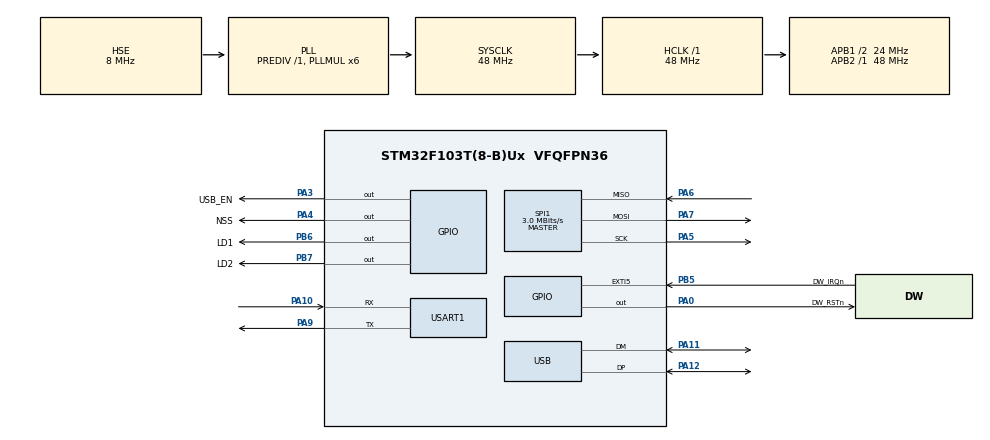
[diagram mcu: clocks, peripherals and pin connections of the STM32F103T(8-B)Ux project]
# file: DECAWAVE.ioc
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Mcu.Family=STM32F1
Mcu.Name=STM32F103T(8-B)Ux
Mcu.Package=VFQFPN36
NVIC.EXTI9_5_IRQn=true\:0\:0\:false\:false\:true\:true\:true\:true
NVIC.PriorityGroup=NVIC_PRIORITYGROUP_4
NVIC.USB_LP_CAN1_RX0_IRQn=true\:0\:0\:false\:false\:true\:false\:true\:true
PA0-WKUP.GPIO_Label=DW_RSTn
PA0-WKUP.GPIO_ModeDefaultOutputPP=GPIO_MODE_OUTPUT_OD
PA0-WKUP.GPIO_PuPd=GPIO_NOPULL
PA0-WKUP.Signal=GPIO_Output
PA10.Mode=Asynchronous
PA10.Signal=USART1_RX
PA11.Mode=Device
PA11.Signal=USB_DM
PA12.Mode=Device
PA12.Signal=USB_DP
PA13.Mode=Serial_Wire
PA13.Signal=SYS_JTMS-SWDIO
PA14.Mode=Serial_Wire
PA14.Signal=SYS_JTCK-SWCLK
PA3.GPIO_Label=USB_EN
PA3.PinState=GPIO_PIN_SET
PA3.Signal=GPIO_Output
PA4.GPIO_Label=NSS
PA4.PinState=GPIO_PIN_SET
PA4.Signal=GPIO_Output
PA5.Mode=Full_Duplex_Master
PA5.Signal=SPI1_SCK
PA6.Mode=Full_Duplex_Master
PA6.Signal=SPI1_MISO
PA7.Mode=Full_Duplex_Master
PA7.Signal=SPI1_MOSI
PA9.Mode=Asynchronous
PA9.Signal=USART1_TX
PB5.GPIO_Label=DW_IRQn
PB5.GPIO_ModeDefaultEXTI=GPIO_MODE_IT_RISING_FALLING
PB5.Signal=GPXTI5
PB6.GPIO_Label=LD1
PB6.PinState=GPIO_PIN_SET
PB6.Signal=GPIO_Output
PB7.GPIO_Label=LD2
PB7.PinState=GPIO_PIN_RESET
PB7.Signal=GPIO_Output
PD0-OSC_IN.Mode=HSE-External-Oscillator
PD0-OSC_IN.Signal=RCC_OSC_IN
PD1-OSC_OUT.Mode=HSE-External-Oscillator
PD1-OSC_OUT.Signal=RCC_OSC_OUT
ProjectManager.HeapSize=0x200
ProjectManager.StackSize=0x400
ProjectManager.TargetToolchain=STM32CubeIDE
RCC.AHBFreq_Value=48000000
RCC.APB1CLKDivider=RCC_HCLK_DIV2
RCC.APB1Freq_Value=24000000
RCC.APB1TimFreq_Value=48000000
RCC.APB2Freq_Value=48000000
RCC.APB2TimFreq_Value=48000000
RCC.HCLKFreq_Value=48000000
RCC.PLLMUL=RCC_PLL_MUL6
RCC.PLLSourceVirtual=RCC_PLLSOURCE_HSE
RCC.SYSCLKFreq_VALUE=48000000
RCC.SYSCLKSource=RCC_SYSCLKSOURCE_PLLCLK
RCC.USBFreq_Value=48000000
SPI1.BaudRatePrescaler=SPI_BAUDRATEPRESCALER_16
SPI1.CLKPolarity=SPI_POLARITY_LOW
SPI1.CalculateBaudRate=3.0 MBits/s
SPI1.Direction=SPI_DIRECTION_2LINES
SPI1.Mode=SPI_MODE_MASTER
SPI1.VirtualType=VM_MASTER
USART1.VirtualMode=VM_ASYNC
USB_DEVICE.CLASS_NAME_FS=CDC
USB_DEVICE.MANUFACTURER_STRING=Agora
USB_DEVICE.VirtualMode=Cdc
USB_DEVICE.VirtualModeFS=Cdc_FS
VP_USB_DEVICE_VS_USB_DEVICE_CDC_FS.Mode=CDC_FS
board=custom

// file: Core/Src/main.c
/* USER CODE BEGIN Header */
/**
 ******************************************************************************
 * @file           : main.c
 * @brief          : Main program body
 ******************************************************************************
 * @attention
 *
 * Copyright (c) 2025 STMicroelectronics.
 * All rights reserved.
 *
 * This software is licensed under terms that can be found in the LICENSE file
 * in the root directory of this software component.
 * If no LICENSE file comes with this software, it is provided AS-IS.
 *
 ******************************************************************************
 */
/* USER CODE END Header */
#include "main.h"
#include "usb_device.h"

/* USER CODE BEGIN Includes */
#include "user_functions.h"

/* USER CODE END Includes */

SPI_HandleTypeDef hspi1;

UART_HandleTypeDef huart1;

void SystemClock_Config(void);
static void MX_GPIO_Init(void);
static void MX_SPI1_Init(void);
static void MX_USART1_UART_Init(void);

int main(void) {

	/* MCU Configuration--------------------------------------------------------*/

	/* Reset of all peripherals, Initializes the Flash interface and the Systick. */
	HAL_Init();

	/* Configure the system clock */
	SystemClock_Config();

	/* Initialize all configured peripherals */
	MX_GPIO_Init();
	MX_SPI1_Init();
	MX_USB_DEVICE_Init();
	MX_USART1_UART_Init();
	/* USER CODE BEGIN 2 */
	setup();
	/* USER CODE END 2 */

	/* Infinite loop */
	while (1) {

		/* USER CODE BEGIN 3 */
		loop();
		/* USER CODE END 3 */
	}
}

void SystemClock_Config(void) {
	RCC_OscInitTypeDef RCC_OscInitStruct = { 0 };
	RCC_ClkInitTypeDef RCC_ClkInitStruct = { 0 };
	RCC_PeriphCLKInitTypeDef PeriphClkInit = { 0 };

	/** Initializes the RCC Oscillators according to the specified parameters
	 * in the RCC_OscInitTypeDef structure.
	 */
	RCC_OscInitStruct.OscillatorType = RCC_OSCILLATORTYPE_HSE;
	RCC_OscInitStruct.HSEState = RCC_HSE_ON;
	RCC_OscInitStruct.HSEPredivValue = RCC_HSE_PREDIV_DIV1;
	RCC_OscInitStruct.HSIState = RCC_HSI_ON;
	RCC_OscInitStruct.PLL.PLLState = RCC_PLL_ON;
	RCC_OscInitStruct.PLL.PLLSource = RCC_PLLSOURCE_HSE;
	RCC_OscInitStruct.PLL.PLLMUL = RCC_PLL_MUL6;
	if (HAL_RCC_OscConfig(&RCC_OscInitStruct) != HAL_OK) {
		Error_Handler();
	}

	/** Initializes the CPU, AHB and APB buses clocks
	 */
	RCC_ClkInitStruct.ClockType = RCC_CLOCKTYPE_HCLK | RCC_CLOCKTYPE_SYSCLK
			| RCC_CLOCKTYPE_PCLK1 | RCC_CLOCKTYPE_PCLK2;
	RCC_ClkInitStruct.SYSCLKSource = RCC_SYSCLKSOURCE_PLLCLK;
	RCC_ClkInitStruct.AHBCLKDivider = RCC_SYSCLK_DIV1;
	RCC_ClkInitStruct.APB1CLKDivider = RCC_HCLK_DIV2;
	RCC_ClkInitStruct.APB2CLKDivider = RCC_HCLK_DIV1;

	if (HAL_RCC_ClockConfig(&RCC_ClkInitStruct, FLASH_LATENCY_1) != HAL_OK) {
		Error_Handler();
	}
	PeriphClkInit.PeriphClockSelection = RCC_PERIPHCLK_USB;
	PeriphClkInit.UsbClockSelection = RCC_USBCLKSOURCE_PLL;
	if (HAL_RCCEx_PeriphCLKConfig(&PeriphClkInit) != HAL_OK) {
		Error_Handler();
	}
}

static void MX_SPI1_Init(void) {

	/* SPI1 parameter configuration*/
	hspi1.Instance = SPI1;
	hspi1.Init.Mode = SPI_MODE_MASTER;
	hspi1.Init.Direction = SPI_DIRECTION_2LINES;
	hspi1.Init.DataSize = SPI_DATASIZE_8BIT;
	hspi1.Init.CLKPolarity = SPI_POLARITY_LOW;
	hspi1.Init.CLKPhase = SPI_PHASE_1EDGE;
	hspi1.Init.NSS = SPI_NSS_SOFT;
	hspi1.Init.BaudRatePrescaler = SPI_BAUDRATEPRESCALER_16;
	hspi1.Init.FirstBit = SPI_FIRSTBIT_MSB;
	hspi1.Init.TIMode = SPI_TIMODE_DISABLE;
	hspi1.Init.CRCCalculation = SPI_CRCCALCULATION_DISABLE;
	hspi1.Init.CRCPolynomial = 10;
	if (HAL_SPI_Init(&hspi1) != HAL_OK) {
		Error_Handler();
	}

}

static void MX_USART1_UART_Init(void) {

	huart1.Instance = USART1;
	huart1.Init.BaudRate = 115200;
	huart1.Init.WordLength = UART_WORDLENGTH_8B;
	huart1.Init.StopBits = UART_STOPBITS_1;
	huart1.Init.Parity = UART_PARITY_NONE;
	huart1.Init.Mode = UART_MODE_TX_RX;
	huart1.Init.HwFlowCtl = UART_HWCONTROL_NONE;
	huart1.Init.OverSampling = UART_OVERSAMPLING_16;
	if (HAL_UART_Init(&huart1) != HAL_OK) {
		Error_Handler();
	}

}

static void MX_GPIO_Init(void) {
	GPIO_InitTypeDef GPIO_InitStruct = { 0 };

	/* GPIO Ports Clock Enable */
	__HAL_RCC_GPIOD_CLK_ENABLE();
	__HAL_RCC_GPIOA_CLK_ENABLE();
	__HAL_RCC_GPIOB_CLK_ENABLE();

	/*Configure GPIO pin Output Level */
	HAL_GPIO_WritePin(DW_RSTn_GPIO_Port, DW_RSTn_Pin, GPIO_PIN_RESET);

	/*Configure GPIO pin Output Level */
	HAL_GPIO_WritePin(GPIOA, USB_EN_Pin | NSS_Pin, GPIO_PIN_SET);

	/*Configure GPIO pin Output Level */
	HAL_GPIO_WritePin(LD1_GPIO_Port, LD1_Pin, GPIO_PIN_SET);

	/*Configure GPIO pin Output Level */
	HAL_GPIO_WritePin(LD2_GPIO_Port, LD2_Pin, GPIO_PIN_RESET);

	/*Configure GPIO pin : DW_RSTn_Pin */
	GPIO_InitStruct.Pin = DW_RSTn_Pin;
	GPIO_InitStruct.Mode = GPIO_MODE_OUTPUT_OD;
	GPIO_InitStruct.Pull = GPIO_NOPULL;
	GPIO_InitStruct.Speed = GPIO_SPEED_FREQ_LOW;
	HAL_GPIO_Init(DW_RSTn_GPIO_Port, &GPIO_InitStruct);

	/*Configure GPIO pins : USB_EN_Pin NSS_Pin */
	GPIO_InitStruct.Pin = USB_EN_Pin | NSS_Pin;
	GPIO_InitStruct.Mode = GPIO_MODE_OUTPUT_PP;
	GPIO_InitStruct.Pull = GPIO_NOPULL;
	GPIO_InitStruct.Speed = GPIO_SPEED_FREQ_LOW;
	HAL_GPIO_Init(GPIOA, &GPIO_InitStruct);

	/*Configure GPIO pin : DW_IRQn_Pin */
	GPIO_InitStruct.Pin = DW_IRQn_Pin;
	GPIO_InitStruct.Mode = GPIO_MODE_IT_RISING_FALLING;
	GPIO_InitStruct.Pull = GPIO_NOPULL;
	HAL_GPIO_Init(DW_IRQn_GPIO_Port, &GPIO_InitStruct);

	/*Configure GPIO pins : LD1_Pin LD2_Pin */
	GPIO_InitStruct.Pin = LD1_Pin | LD2_Pin;
	GPIO_InitStruct.Mode = GPIO_MODE_OUTPUT_PP;
	GPIO_InitStruct.Pull = GPIO_NOPULL;
	GPIO_InitStruct.Speed = GPIO_SPEED_FREQ_LOW;
	HAL_GPIO_Init(GPIOB, &GPIO_InitStruct);

	/* EXTI interrupt init*/
	HAL_NVIC_SetPriority(EXTI9_5_IRQn, 0, 0);
	HAL_NVIC_EnableIRQ(EXTI9_5_IRQn);

}

void Error_Handler(void) {
	__disable_irq();
	while (1) {
	}
}
